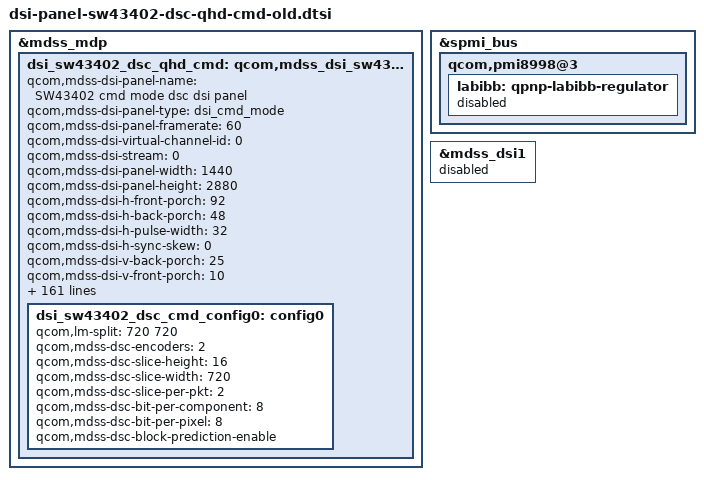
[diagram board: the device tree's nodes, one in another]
/* Copyright (c) 2014, Code Aurora Forum. All rights reserved.
 *
 * This program is free software; you can redistribute it and/or modify
 * it under the terms of the GNU General Public License version 2 and
 * only version 2 as published by the Free Software Foundation.
 *
 * This program is distributed in the hope that it will be useful,
 * but WITHOUT ANY WARRANTY; without even the implied warranty of
 * MERCHANTABILITY or FITNESS FOR A PARTICULAR PURPOSE.  See the
 * GNU General Public License for more details.
 */

#include "dsi-panel-sw43402-dynamic-resolution-switching.dtsi"

&mdss_mdp {
    dsi_sw43402_dsc_qhd_cmd: qcom,mdss_dsi_sw43402_dsc_qhd_cmd {
        qcom,mdss-dsi-panel-name = "SW43402 cmd mode dsc dsi panel";
		qcom,mdss-dsi-panel-type = "dsi_cmd_mode";
		qcom,mdss-dsi-panel-framerate = <60>;
		qcom,mdss-dsi-virtual-channel-id = <0>;
		qcom,mdss-dsi-stream = <0>;
		qcom,mdss-dsi-panel-width = <1440>;
		qcom,mdss-dsi-panel-height = <2880>;
		qcom,mdss-dsi-h-front-porch = <92>;
		qcom,mdss-dsi-h-back-porch = <48>;
		qcom,mdss-dsi-h-pulse-width = <32>;
		qcom,mdss-dsi-h-sync-skew = <0>;
		qcom,mdss-dsi-v-back-porch = <25>;
		qcom,mdss-dsi-v-front-porch = <10>;
		qcom,mdss-dsi-v-pulse-width = <1>;
		qcom,mdss-dsi-h-left-border = <0>;
		qcom,mdss-dsi-h-right-border = <0>;
		qcom,mdss-dsi-v-top-border = <0>;
		qcom,mdss-dsi-v-bottom-border = <0>;
		qcom,mdss-dsi-panel-timings = [00 14 05 05 08 0E 04 05 04 03 04 00];
		qcom,mdss-dsi-t-clk-post = <0x06>;
		qcom,mdss-dsi-t-clk-pre = <0x20>;
		qcom,mdss-dsi-bpp = <24>;
		qcom,mdss-dsi-color-order = "rgb_swap_rgb";
		qcom,mdss-dsi-underflow-color = <0xff>;
		qcom,mdss-dsi-border-color = <0>;
		qcom,mdss-dsi-h-sync-pulse = <0>;
		qcom,mdss-dsi-traffic-mode = "burst_mode";
		qcom,mdss-dsi-lane-map = "lane_map_0123";
		qcom,mdss-dsi-bllp-eof-power-mode;
		qcom,mdss-dsi-bllp-power-mode;
		qcom,partial-update-enabled = "single_roi";
		qcom,panel-roi-alignment = <1440 0 1440 16 1440 16>;
		qcom,mdss-dsi-lane-0-state;
		qcom,mdss-dsi-lane-1-state;
		qcom,mdss-dsi-lane-2-state;
		qcom,mdss-dsi-lane-3-state;
		qcom,mdss-dsi-reset-sequence = <1 10>, <0 2>, <1 10>;
		qcom,mdss-dsi-bl-max-level = <511>;
		qcom,mdss-brightness-max-level = <511>;
		qcom,default-brightness = <158>;
		qcom,mdss-dsi-dma-trigger = "trigger_sw";
		qcom,mdss-dsi-mdp-trigger = "none";
		qcom,mdss-dsi-te-pin-select = <1>;
		qcom,mdss-dsi-wr-mem-start = <0x2c>;
		qcom,mdss-dsi-wr-mem-continue = <0x3c>;
		qcom,mdss-dsi-te-dcs-command = <1>;
		qcom,mdss-dsi-te-check-enable;
		qcom,mdss-dsi-te-using-te-pin;
		qcom,mdss-dsi-lp11-init;
		qcom,mdss-dsi-tx-eot-append;
		qcom,mdss-mdp-transfer-time-us = <15000>;
		qcom,ulps-enabled;
		qcom,panel-allow-phy-poweroff;
		qcom,mdss-dsi-force-clock-lane-hs = <1>;

		qcom,mdss-dsi-panel-hdr-enabled;
		qcom,mdss-dsi-panel-hdr-color-primaries = <14880 15935 32435 16555 14945 30910 7790 3415>;
		qcom,mdss-dsi-panel-peak-brightness = <5643000>;		/* max. 500nits */
		qcom,mdss-dsi-panel-blackness-level = <6134>;

		qcom,mdss-dsi-on-command = [
			39 01 00 00 00 00 03 B0 20 43
			15 01 00 00 00 00 02 3D 00
			39 01 00 00 00 00 03 DF 4B 70
			15 01 00 00 00 00 02 F2 00
			39 01 00 00 01 00 03 FF 03 00
			05 01 00 00 14 00 01 35
			05 01 00 00 14 00 01 11
			15 01 00 00 00 00 02 51 03
			15 01 00 00 00 00 02 53 07
			15 01 00 00 00 00 02 55 0C
			39 01 00 00 00 00 03 B0 A5 00
			39 01 00 00 00 00 05 E8 08 90 10 25
			39 01 00 00 00 00 03 FB 03 77
			39 01 00 00 14 00 06 ED 13 00 07 00 13
			39 01 00 00 46 00 0F E2 20 0D 08 A8 0A AA 04 A4 80 80 80 5C 5C 5C
			];
		qcom,mdss-dsi-on-command-state = "dsi_lp_mode";

		qcom,mdss-dsi-post-panel-on-command = [
			39 01 00 00 3C 00 03 B0 A5 00
			05 01 00 00 00 00 01 29
			];

		qcom,mdss-dsi-off-command = [
			39 01 00 00 00 00 08 CA 00 46 00 46 00 16 11
			39 01 00 00 00 00 1F CB 02 D8 00 02 D8 00 02 D8 00 02 D8 00 02 D8 00 02 D8 00 02 D8 00 02 D8 00 02 D8 00 02 D8 00
			39 01 00 00 00 00 13 CC 02 D8 00 02 D8 00 02 D8 00 0B 5E 00 0B 5E 00 55 12 13
			39 01 00 00 00 00 05 E8 08 90 10 25
			05 01 00 00 00 00 01 28
			05 01 00 00 96 00 01 10
			];
		qcom,mdss-dsi-off-command-state = "dsi_lp_mode";

		lge,mdss-dsi-disp-ctrl-command-1 = [
		    15 01 00 00 00 00 02 53 07
                    ];
		lge,mdss-dsi-disp-ctrl-command-1-state = "dsi_hs_mode";
		lge,mdss-dsi-disp-ctrl-command-2 = [
		    15 01 00 00 00 00 02 55 0C
                    ];
		lge,mdss-dsi-disp-ctrl-command-2-state = "dsi_hs_mode";

		lge,mdss-dsi-bc-dim-command = [
		    15 01 00 00 00 00 02 5E 00
                    ];
		lge,mdss-dsi-bc-default_command = [
                    39 01 00 00 00 00 19 B8 CA 30 30 20 20 05 00 00 00 39 05 00 00 00 40 00 10 44 dd 15 15 20 00 00
                    ];
		qcom,mdss-dsi-lp-mode-on = [15 01 00 00 00 00 02 53 08];
		qcom,mdss-dsi-lp-mode-off = [15 01 00 00 00 00 02 53 00];
		lge,mdss-dsi-d65-command = [
			39 01 00 00 00 00 0A CF 03 05 AF 03 05 AF 03 01 6B
			39 01 00 00 00 00 1C D0 00 FF 85 0B 98 15 92 13 85 00 EC 81 05 90 0A 86 03 77 00 B8 77 EE 65 DC 54 CB 42
			];
		lge,mdss-dsi-cm-default-command = [
			39 01 00 00 00 00 0A CF 00 00 00 00 00 00 00 00 00
			39 01 00 00 00 00 1C D0 00 00 00 00 00 00 00 00 00 00 00 00 00 00 00 00 00 00 00 00 00 00 00 00 00 00 00
			];
		lge,mdss-dsi-hs-command-state = "dsi_hs_mode";

		lge,mode-change-cmds-panel-on-to-doze-suspend = [
			39 01 00 00 00 00 03 B0 A5 00
			39 01 00 00 00 00 0A D2 1A BC 02 BC 01 00 06 FF 00
			39 01 00 00 00 00 08 CA 00 46 00 46 00 16 11
			39 01 00 00 00 00 1F CB 02 D8 00 02 D8 00 02 D8 00 02 D8 00 02 D8 00 02 D8 00 02 D8 00 02 D8 00 02 D8 00 02 D8 00
			39 01 00 00 00 00 13 CC 02 D8 00 02 D8 00 02 D8 00 0B 5E 00 0B 5E 00 55 12 13
			39 01 00 00 00 00 09 E5 04 04 03 03 56 21 33 0A
			39 01 00 00 00 00 13 E7 00 0D 76 1A 00 00 0D 44 0D 76 0D 0D 00 0D 0D 0D 4A 00
			39 01 00 00 46 00 0F E2 20 03 08 A8 0A AA 04 A4 80 80 80 5C 5C 5C
			05 01 00 00 00 00 01 34
			39 01 00 00 00 00 05 30 00 00 0B 3F
			15 01 00 00 00 00 02 31 00
			15 01 00 00 00 00 02 5E 00
			05 01 00 00 00 00 01 12
			39 01 00 00 00 00 0B E0 18 10 11 00 00 20 00 00 20 20
			05 01 00 00 55 00 01 39
			05 01 00 00 00 00 01 35
			39 01 00 00 00 00 08 CA 00 46 00 46 00 16 11
			39 01 00 00 00 00 1F CB 20 01 CC 20 01 CC 20 01 CC 11 23 AB 11 23 AB 01 D9 F5 01 D9 F5 02 79 55 02 79 55 02 B3 1A
			39 01 00 00 00 00 13 CC 20 01 CC 20 6D 60 11 23 AB 29 18 1E 29 18 1E 55 12 13
			];

		lge,mode-change-cmds-doze-suspend-to-panel-on = [
			39 01 00 00 00 00 08 CA 00 46 00 46 00 16 11
			39 01 00 00 00 00 1F CB 02 D8 00 02 D8 00 02 D8 00 02 D8 00 02 D8 00 02 D8 00 02 D8 00 02 D8 00 02 D8 00 02 D8 00
			39 01 00 00 00 00 13 CC 02 D8 00 02 D8 00 02 D8 00 0B 5E 00 0B 5E 00 55 12 13
			39 01 00 00 28 00 0F E2 20 0D 08 A8 0A AA 04 A4 80 80 80 5C 5C 5C
			05 01 00 00 00 00 01 34
			05 01 00 00 00 00 01 38
			15 01 00 00 00 00 02 31 00
			15 01 00 00 00 00 02 51 03
			15 01 00 00 00 00 02 5E 00
			05 01 00 00 55 00 01 13
			05 01 00 00 00 00 01 35
			39 01 00 00 00 00 08 CA 00 46 00 46 00 16 11
			39 01 00 00 00 00 1F CB 20 01 CC 20 01 CC 20 01 CC 11 23 AB 11 23 AB 01 D9 F5 01 D9 F5 02 79 55 02 79 55 02 B3 1A
			39 01 00 00 00 00 13 CC 20 01 CC 20 6D 60 11 23 AB 29 18 1E 29 18 1E 55 12 13
			];

		lge,mode-change-cmds-doze-suspend-to-doze = [
			39 01 00 00 00 00 07 E4 00 04 00 48 34 02
			];
		lge,mode-change-cmds-doze-to-doze-suspend = [
			39 01 00 00 00 00 07 E4 30 04 00 48 34 02
			];
		lge,bist-on-cmds = [
			39 01 00 00 21 00 09 EF 03 00 00 00 00 00 13 01
			];
		lge,change-partial-area-cmds = [
			/* PTLAR */
			39 00 00 00 00 00 05 30 00 00 0B 3F
			/* PLTAC */
			15 01 00 00 00 00 02 31 00
			];
		lge,bist-off-cmds = [
			39 01 00 00 00 00 09 EF 00 00 00 00 00 00 13 01
			];

		lge,internal-test-command-aod = [
			05 01 00 00 00 00 01 39
			39 01 00 00 00 00 03 B0 A5 00
			05 01 00 00 00 00 01 12
			39 01 00 00 00 00 0A D2 01 EE 02 D0 01 00 06 02 10
			39 01 00 00 00 00 05 30 05 A5 08 74
			39 01 00 00 00 00 02 31 00
			39 01 00 00 00 00 02 5E 8D
			];
		lge,internal-test-command-aod-state = "dsi_hs_mode";
		lge,internal-test-command-orbit = [
			39 01 00 00 00 00 03 B0 A5 00
			15 01 00 00 00 00 02 5E 80
			39 01 00 00 00 00 0A D2 1A BC 02 D0 0A 00 0A 0A 00
			];
		lge,internal-test-command-orbit-state = "dsi_hs_mode";
		lge,internal-test-command-frc = [
			39 01 00 00 00 00 03 B0 A5 00
			39 01 00 00 00 00 03 FB 03 77
			];
		lge,internal-test-command-frc-state = "dsi_hs_mode";
		lge,internal-test-command-power-set1 = [
			39 01 00 00 00 00 03 B0 A5 00
			39 01 00 00 00 00 09 E5 04 06 13 13 56 21 FF 0A
			39 01 00 00 00 00 09 E5 04 06 03 03 56 21 FF 0A
			39 01 00 00 00 00 0F E2 20 0d 08 A8 0A AA 04 A4 80 80 80 5C 5C 5C
			39 01 00 00 00 00 13 E7 00 0D 76 1A 00 00 0D 44 0D 76 0D 0D 00 0D 0D 0D 4A 00
			15 01 00 00 01 00 02 3F 03
			];
		lge,internal-test-command-power-set1-state = "dsi_hs_mode";
		lge,internal-test-command-power-set2 = [
			39 01 00 00 00 00 03 B0 A5 00
			39 01 00 00 01 00 07 E4 40 04 00 48 34 02
			];
		lge,internal-test-command-power-set2-state = "dsi_hs_mode";
		lge,internal-test-command-power-set3 = [
			39 01 00 00 00 00 03 B0 A5 00
			39 01 00 00 00 00 07 E4 40 44 00 48 34 02
			39 01 00 00 01 00 07 E4 40 84 00 48 34 02
			];
		lge,internal-test-command-power-set3-state = "dsi_hs_mode";
		lge,memory-error-detect-command = [
			39 01 00 00 00 00 03 EE C0 10
			];
		lge,esd-detect-command = [
			39 01 00 00 00 00 03 EE D0 0D
			];
		lge,digital-gamma-cmds-2500K = [
			39 00 00 00 00 00 0A CF 03 05 AF 03 01 6A 02 00 55
			39 01 00 00 00 00 1C D0 00 FF 80 00 80 00 80 00 80 00 4F 6A D4 3E A8 12 7C E6 00 33 46 8D D3 1A 60 A6 ED
			];
		lge,digital-gamma-cmds-3000K = [
			39 00 00 00 00 00 0A CF 03 05 AF 03 01 6B 02 00 56
			39 01 00 00 00 00 1C D0 00 FF 80 00 80 00 80 00 80 00 77 6F DE 4D BC 2B 9A 09 00 8D 52 A3 F5 47 98 EA 3C
			];
		lge,digital-gamma-cmds-3500K = [
			39 00 00 00 00 00 0A CF 03 05 AF 03 01 6B 02 01 5A
			39 01 00 00 00 00 1C D0 00 FF 80 00 80 00 80 00 80 00 95 73 E5 58 CB 3D B0 23 00 DB 5C B7 13 6E CA 25 81
			];
		lge,digital-gamma-cmds-4000K = [
			39 00 00 00 00 00 0A CF 03 05 AF 03 01 6B 03 01 5A
			39 01 00 00 00 00 1C D0 00 FF 80 00 80 00 80 00 80 00 AD 76 EC 61 D7 4D C3 38 00 19 63 C6 2A 8D F0 53 B6
			];
		lge,digital-gamma-cmds-4500K = [
			39 00 00 00 00 00 0A CF 03 05 AF 03 01 6B 03 01 6A
			39 01 00 00 00 00 1C D0 00 FF 80 00 80 00 80 00 80 00 C0 78 F0 68 E0 58 D0 48 00 4B 69 D3 3C A6 0F 79 E2
			];
		lge,digital-gamma-cmds-5000K = [
			39 00 00 00 00 00 0A CF 03 05 AF 03 01 6B 03 01 6B
			39 01 00 00 00 00 1C D0 00 FF 80 00 80 00 80 00 80 00 CF 7A F4 6E E8 62 DC 56 00 74 6F DD 4C BA 29 98 06
			];
		lge,digital-gamma-cmds-5500K = [
			39 00 00 00 00 00 0A CF 03 05 AF 03 01 6B 03 01 6B
			39 01 00 00 00 00 1C D0 00 FF 80 00 80 00 80 00 80 00 DD 7C F8 73 EF 6B E7 62 00 97 73 E6 59 CC 3F B2 25
			];
		lge,digital-gamma-cmds-6000K = [
			39 00 00 00 00 00 0A CF 03 05 AF 03 01 6B 03 01 6B
			39 01 00 00 00 00 1C D0 00 FF 80 00 80 00 80 00 80 00 E9 7D FA 78 F5 72 EF 6D 00 B6 77 EE 65 DC 53 C9 40
			];
		lge,digital-gamma-cmds-6500K = [
			39 00 00 00 00 00 0A CF 03 05 AF 03 01 6B 03 01 6B
			39 01 00 00 00 00 1C D0 00 FF 80 00 80 00 80 00 80 00 F2 7E FD 7B F9 78 F6 74 00 D1 7A F4 6F E9 63 DD 58
			];
		lge,digital-gamma-cmds-7000K = [
			39 00 00 00 00 00 0A CF 03 05 AF 03 01 6B 03 01 6B
			39 01 00 00 00 00 1C D0 00 FF 80 00 80 00 80 00 80 00 F9 7F FE 7E FD 7C FB 7B 00 E8 7D FA 78 F5 72 EF 6C
			];
		lge,digital-gamma-cmds-dummy = [
			39 00 00 00 00 00 0A CF 00 00 00 00 00 00 00 00 00
			39 01 00 00 00 00 1C D0 00 00 00 00 00 00 00 00 00 00 00 00 00 00 00 00 00 00 00 00 00 00 00 00 00 00 00
			];
		lge,blmap = <
			3
			27 27 27 27 27 27 27 27 27 27 27 27 27 27 27 28 28 28 29 29
			30 30 31 32 33 34 34 34 35 35 36 36 37 38 39 40 41 42 42 42
			43 44 45 45 46 47 48 49 49 49 50 51 52 52 52 53 53 54 55 56
			56 56 57 57 58 58 58 59 59 60 60 60 61 61 62 62 62 63 64 65
			65 66 67 68 69 70 71 71 72 73 73 74 74 75 76 77 79 79 80 81
			82 84 84 84 85 86 88 89 91 92 93 94 95 96 96 98 98 99 100 101
			102 103 104 105 105 107 107 108 110 110 110 111 112 114 115 116 116 117 118 118
			119 119 120 121 123 125 125 125 126 126	127 127 128 128 129 131 133 134 134 135
			136 136 137 137 138 139 140 141 141 142	143 144 146 146 147 148 149 150 151 152
			154 156 158 159 163 163 165 165 167 167	167 168 168 169 170 170 171 172 173 174
			174 176 176 176 178 179 180 180 181 182	182 183 183 183 185 186 188 189 190 191
			193 193 193 194 195 197 198 198 198 199	200 202 203 204 204 205 206 207 208 209
			210 211 211 212 213 215 215 216 217 218	218 220 220 221 223 223	223 223 223 223
			223 223 223 223 223 223	223 223 223 223	223 223 223 223 223 223	224 224 224 224
			224 224 224 224 225 225	225 225 225 226	226 226 226 226 226 226	227 227 227 227
			227 227 227 228 228 228	228 228 229 229	229 229 229 229 229 229	229 229 230 230
			230 230 230 231 231 231	231 231 232 232	232 232 232 232 232 232	232 232 233 233
			234 234 234 234 234 235	235 236 236 236	237 237 237 237 237 238	238 238 238 238
			239 239 239 239 239 239	239 239 239 239	239 239 239 239 239 239	239 239 239 239
			239 239 239 239 239 239	239 239 239 239	239 239 239 239 239 239	239 239 239 239
			239 239 239 239 239 239 239 239 239 239	239 239 239 239 239 239 239 239 239 239
			239 239 239 239 239 239 239 239 239 239	239 239 239 239 239 239 239 239 239 239
			239 239 239 239 239 239 239 239 239 239	239 239 239 239 239 239 239 239 239 239
			239 239 239 239 239 239 239 239 239 239	239 239 239 239 239 239 239 239 239 239
			239 239 239 239 239 239 239 239 239 239	239 239 239 239 239 239 239 239 239 239
			239 239 239 239 239 239 239 239 239 239	239
			>;
		lge,blmap-ve = <
			3
			37 37 37 37 37 37 37 37 37 37 37 37 37 37 37 37 37 37 38 38
			38 38 39 40 40 40 40 41 42 42 43 43 43 44 45 46 47 48 48 48
			49 50 51 51 51 52 53 54 54 54 55 55 56 56 56 57 58 59 59 60
			60 60 61 61 62 62 62 63 64 65 65 66 67 68 69 70 71 72 72 73
			73 74 75 76 78 79 81 81 82 83 84 85 86 87 88 90 92 93 96 95
			95 96 97 98 100 101 103 105 105 108 108 107 108 110 110 111 112 113 114 114
			115 116 117 119 119 120 121 123 125 125 125 126 126 127 128 129 129 130 131 132
			134 135 136 137 137 138 139 140 141 142 143 144 145 146 147 148 149 151 161 153
			155 164 162 162 163 164 165 166 166 166 167 168 169 170 171 173 173 174 174 175
			176 177 178 180 182 182 182 183 184 185 186 187 189 190 192 192 193 194 195 197
			197 197 198 199 201 202 203 204 205 206 207 208 209 210 211 212 214 214 215 216
			217 219 219 220 221 222 223 223 223 223 223 224 224 225 225 225 226 226 226 226
			226 227 227 228 228 228 229 229 230 230 230 231 231 232 233 233 233 233 233 233
			233 233 233 233 233 233 233 233 233 233	233 233 233 234 234 234 234 234 234 234
			234 234 234 234 234 234 234 234 234 234	235 235 235 235 235 235 235 235 235 235
			235 235 235 235 235 236 236 236 236 236	236 236 236 236 236 236 236 236 236 236
			237 237 237 237 237 237 237 237 237 237	237 237 237 237 237 238 238 238 238 238
			238 238 238 238 238 238 238 238 238 238	239 239 239 239 239 239 239 239 239 239
			239 239 239 239 239 239 239 239 239 239	239 239 239 239 239 239 239 239 239 239
			239 239 239 239 239 239 239 239 239 239	239 239 239 239 239 239 239 239 239 239
			239 239 239 239 239 239 239 239 239 239	239 239 239 239 239 239 239 239 239 239
			239 239 239 239 239 239 239 239 239 239	239 239 239 239 239 239 239 239 239 239
			239 239 239 239 239 239 239 239 239 239	239 239 239 239 239 239 239 239 239 239
			239 239 239 239 239 239 239 239 239 239	239 239 239 239 239 239 239 239 239 239
			239 239 239 239 239 239 239 239 239 239	239 239 239 239 239 239 239 239 239 239
			239 239 239 239 239 239 239 239 239 239	239
			>;
		lge,blmap-ex = <
			3
			41 41 41 41 41 41 41 41 41 41 41 41 41 41 41 42 42 42 43 43
			44 44 45 46 47 49 49 49 50 51 53 54 55 56 58 60 61 63 64 65
			67 68 70 71 72 74 76 78 79 81 83 84 86 87 89 91 93 95 97 99
			100 101 103 104 106 107 108 110 113 116 117 119 121 123 125 126 127 129 131 134
			135 136 138 140 142 144 146 147 148 150 152 155 157 159 162 164 166 167 169 171
			173 176 177 178 179 181 183 185 187 189	191 193 195 198 200 202 204 206 209 210
			212 214 216 219 220 222 224 226 228 230	232 234 236 238 240 243 244 245 246 249
			252 252 253 254 254 255 255 255 255 255	255 255 255 255 255 255 255 255 255 255
			255 255 255 255 255 255 255 255 255 255	255 255 255 255 255 255 255 255 255 255
			255 255 255 255 255 255 255 255 255 255	255 255 255 255 255 255 255 255 255 255
			255 255 255 255 255 255 255 255 255 255	255 255 255 255 255 255 255 255 255 255
			255 255 255 255 255 255 255 255 255 255	255 255 255 255 255 255 255 255 255 255
			255 255 255 255 255 255 255 255 255 255	255 255 255 255 255 255 255 255 255 255
			255 255 255 255 255 255 255 255 255 255	255 255 255 255 255 255 255 255 255 255
			255 255 255 255 255 255 255 255 255 255	255 255 255 255 255 255 255 255 255 255
			255 255 255 255 255 255 255 255 255 255	255 255 255 255 255 255 255 255 255 255
			255 255 255 255 255 255 255 255 255 255	255 255 255 255 255 255 255 255 255 255
			255 255 255 255 255 255 255 255 255 255	255 255 255 255 255 255 255 255 255 255
			255 255 255 255 255 255 255 255 255 255	255 255 255 255 255 255 255 255 255 255
			255 255 255 255 255 255 255 255 255 255	255 255 255 255 255 255 255 255 255 255
			255 255 255 255 255 255 255 255 255 255	255 255 255 255 255 255 255 255 255 255
			255 255 255 255 255 255 255 255 255 255	255 255 255 255 255 255 255 255 255 255
			255 255 255 255 255 255 255 255 255 255	255 255 255 255 255 255 255 255 255 255
			255 255 255 255 255 255 255 255 255 255	255 255 255 255 255 255 255 255 255 255
			255 255 255 255 255 255 255 255 255 255	255 255 255 255 255 255 255 255 255 255
			255 255 255 255 255 255 255 255 255 255	255
			>;
		lge,blmap_v1 = <
			3
			30 30 30 30 30 30 30 30 30 30 30 30 30 30 30 30 30 30 31 33
			35 35 36 37 38 39 39 40 41 41 42 42 42 43 44 45 45 45 45 45
			46 47 48 48 48 48 48 49 49 50 51 51 51 51 52 53 53 54 54 55
			55 55 56 56 57 57 57 58 59 60 60 60 61 61 62 62 63 64 65 66
			67 68 69 69 70 71 73 73 74 75 76 77 78 79 80 81 82 82 83 84
			85 86 86 87 88 89 90 90 91 92 93 94 96 98 98 99 100 102 104 105
			106 107 108 109 110 111 112 113 114 114 114 115 116 117 118 120 120 120 121 122
			123 123 123 124 124 125 126 127 128 128 129 129 130 131 132 133 134 135 135 136
			137 138 139 139 140 141 142 143 143 143 144 145 147 147 148 149 149 150 151 152
			153 153 154 155 156 156 157 158 159 160 160 161 162 162 163 164 165 166 167 169
			169 170 171 173 175 177 179 179 180 181 183 185 185 186 187 188 190 191 192 193
			195 196 197 198 199 200 201 202 203 205 206 208 209 210 211 212 213 214 215 216
			217 218 219 221 222 224 226 227 229 230 232 234 236 238 239 239 239 239 239 239
			239 239 240 240 240 240 240 240 240 240 240 240 240 240 240 240 240 241 241 241
			241 241 241 241 241 241 241 241 242 242 242 242 242 243 243 243 243 243 244 244
			244 244 244 245 245 246 246 247 247 247 247 247 247 247 247 248 248 248 248 248
			248 248 248 248 248 248 249 249 249 249 249 249 249 249 250 250 250 250 251 251
			251 251 252 252 252 252 252 252 253 253 253 253 253 253 254 254 254 254 254 254
			255 255 255 255 255 255 255 255 255 255 255 255 255 255 255 255 255 255 255 255
			255 255 255 255 255 255 255 255 255 255 255 255 255 255 255 255 255 255 255 255
			255 255 255 255 255 255 255 255 255 255 255 255 255 255 255 255 255 255 255 255
			255 255 255 255 255 255 255 255 255 255 255 255 255 255 255 255 255 255 255 255
			255 255 255 255 255 255 255 255 255 255 255 255 255 255 255 255 255 255 255 255
			255 255 255 255 255 255 255 255 255 255 255 255 255 255 255 255 255 255 255 255
			255 255 255 255 255 255 255 255 255 255 255 255 255 255 255 255 255 255 255 255
			255 255 255 255 255 255 255 255 255 255 255
			>;
		lge,blmap-ve_v1 = <
			3
			43 43 43 43 43 43 43 43 43 43 43 43 43 43 43 43 43 43 43 43
			44 44 44 44 44 45 45 45 45 45 46 46 46 47 47 48 48 49 49 49
			50 50 51 51 51 52 52 53 53 53 54 54 55 55 56 57 57 58 58 59
			59 59 60 61 62 62 63 64 65 67 67 68 69 70 72 72 73 74 75 77
			77 78 79 80 81 82 84 84 85 86 87 88 89 90 91 91 92 93 95 97
			98 99 100 101 102 104 106 107 109 110 111 112 113 114 114 115 116 117 118 119
			120 121 121 122 122 123 124 124 125 126 127 128 128 129 130 132 132 133 134 134
			135 136 137 138 139 140 141 142 143 143 144 145 146 147 148 149 150 152 152 152
			153 154 156 156 156 157 158 160 160 161 162 162 163 164 165 166 168 170 171 172
			174 175 177 179 181 182 183 185 186 188 189 190 191 192 194 195 196 198 199 200
			201 202 204 205 207 208 209 210 211 213 214 215 216 217 218 220 222 224 226 228
			230 232 233 234 236 237 239 239 239 240 240 241 241 242 242 242 243 243 244 244
			244 245 245 246 246 246 247 247 248 248 248 249 249 250 251 251 251 251 251 251
			251 251 251 251 251 251 251 251 251 251 251 251 251 251 251 251 251 251 251 251
			251 251 251 251 251 251 251 251 251 251 251 251 251 252 252 252 252 252 252 252
			252 252 252 252 252 252 252 252 252 252 252 252 252 252 252 252 252 252 252 252
			253 253 253 253 253 253 253 253 253 253 253 253 253 253 253 253 253 253 254 254
			254 254 254 254 254 254 254 254 254 254 254 254 254 254 255 255 255 255 255 255
			255 255 255 255 255 255 255 255 255 255 255 255 255 255 255 255 255 255 255 255
			255 255 255 255 255 255 255 255 255 255 255 255 255 255 255 255 255 255 255 255
			255 255 255 255 255 255 255 255 255 255 255 255 255 255 255 255 255 255 255 255
			255 255 255 255 255 255 255 255 255 255 255 255 255 255 255 255 255 255 255 255
			255 255 255 255 255 255 255 255 255 255 255 255 255 255 255 255 255 255 255 255
			255 255 255 255 255 255 255 255 255 255 255 255 255 255 255 255 255 255 255 255
			255 255 255 255 255 255 255 255 255 255 255 255 255 255 255 255 255 255 255 255
			255 255 255 255 255 255 255 255 255 255 255
			>;
		lge,blmap-ex_v1 = <
			3
			26 26 26 26 26 26 26 26 27 28 29 31 32 33 34 36 37 38 39 40
			42 43 44 45 47 48 49 50 51 53 54 55 56 58 59 60 62 63 65 67
			68 70 72 73 75 77 78 80 82 83 85 87 88 90 92 93 95 97 98 100
			102 103 105 107 108 110 112 113 115 117 118 120 122 123 125 127 129 131 132 134
			136 138 140 142 144 146 147 149 151 153 155 157 159 160 162 164 166 168 170 172
			174 175 177 179 181 183 185 187 189 191 192 194 196 198 200 201 203 204 205 207
			208 209 211 212 213 214 216 217 218 220 221 222 224 225 225 225 225 225 225 225
			227 228 230 231 233 234 236 238 239 241 242 244 246 247 249 250 252 253 255 255
			255 255 255 255 255 255 255 255 255 255	255 255 255 255 255 255 255 255 255 255
			255 255 255 255 255 255 255 255 255 255	255 255 255 255 255 255 255 255 255 255
			255 255 255 255 255 255 255 255 255 255	255 255 255 255 255 255 255 255 255 255
			255 255 255 255 255 255 255 255 255 255	255 255 255 255 255 255 255 255 255 255
			255 255 255 255 255 255 255 255 255 255	255 255 255 255 255 255 255 255 255 255
			255 255 255 255 255 255 255 255 255 255	255 255 255 255 255 255 255 255 255 255
			255 255 255 255 255 255 255 255 255 255	255 255 255 255 255 255 255 255 255 255
			255 255 255 255 255 255 255 255 255 255	255 255 255 255 255 255 255 255 255 255
			255 255 255 255 255 255 255 255 255 255	255 255 255 255 255 255 255 255 255 255
			255 255 255 255 255 255 255 255 255 255	255 255 255 255 255 255 255 255 255 255
			255 255 255 255 255 255 255 255 255 255	255 255 255 255 255 255 255 255 255 255
			255 255 255 255 255 255 255 255 255 255	255 255 255 255 255 255 255 255 255 255
			255 255 255 255 255 255 255 255 255 255	255 255 255 255 255 255 255 255 255 255
			255 255 255 255 255 255 255 255 255 255	255 255 255 255 255 255 255 255 255 255
			255 255 255 255 255 255 255 255 255 255	255 255 255 255 255 255 255 255 255 255
			255 255 255 255 255 255 255 255 255 255	255 255 255 255 255 255 255 255 255 255
			255 255 255 255 255 255 255 255 255 255	255 255 255 255 255 255 255 255 255 255
			255 255 255 255 255 255 255 255 255 255	255
			>;

		qcom,mode-control-dsi-state = "dsi_lp_mode";
		qcom,mdss-pan-physical-width-dimension = <68>;
		qcom,mdss-pan-physical-height-dimension = <136>;

		qcom,compression-mode = "dsc";
		qcom,config-select = <&dsi_sw43402_dsc_cmd_config0>;

		qcom,mdss-dsc-version = <0x11>;
		qcom,mdss-dsc-scr-version = <0x1>;

		dsi_sw43402_dsc_cmd_config0: config0 {
		        qcom,lm-split = <720 720>;
		        qcom,mdss-dsc-encoders = <2>;
		        qcom,mdss-dsc-slice-height = <16>;
		        qcom,mdss-dsc-slice-width = <720>;
		        qcom,mdss-dsc-slice-per-pkt = <2>;

		        qcom,mdss-dsc-bit-per-component = <8>;
		        qcom,mdss-dsc-bit-per-pixel = <8>;
		        qcom,mdss-dsc-block-prediction-enable;
		};
	};
};
&spmi_bus {
	qcom,pmi8998@3 {
		labibb: qpnp-labibb-regulator {
			status = "disabled";
		};
	};
};
&mdss_dsi1 {
	status = "disabled";
};
